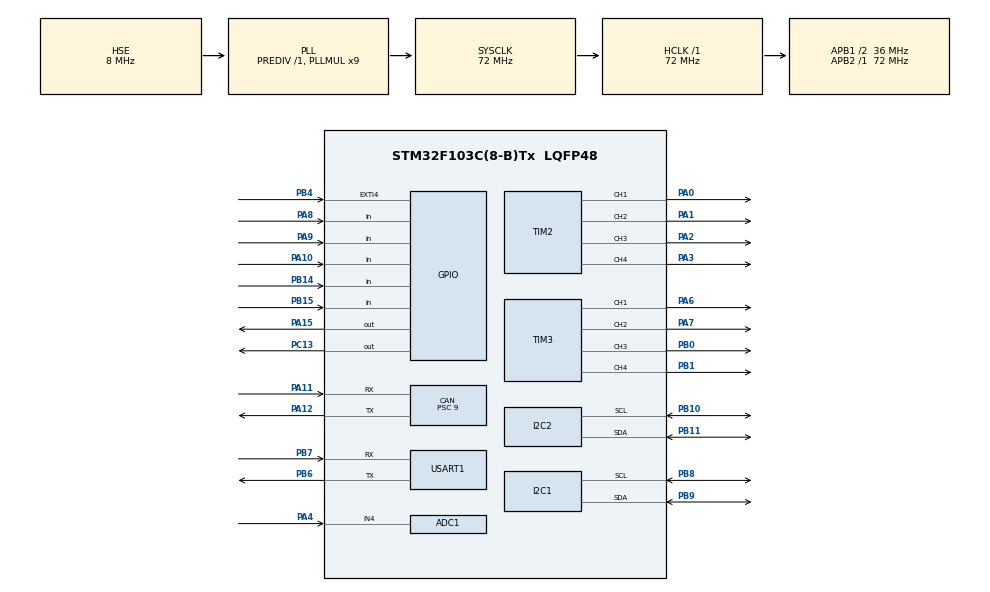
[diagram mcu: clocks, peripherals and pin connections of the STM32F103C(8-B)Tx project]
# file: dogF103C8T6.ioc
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ADC1.Channel-0\#ChannelRegularConversion=ADC_CHANNEL_4
ADC1.Channel-2\#ChannelRegularConversion=ADC_CHANNEL_VREFINT
ADC1.ContinuousConvMode=ENABLE
ADC1.NbrOfConversion=2
ADC1.NbrOfConversionFlag=1
ADC1.Rank-0\#ChannelRegularConversion=1
ADC1.Rank-2\#ChannelRegularConversion=2
ADC1.SamplingTime-0\#ChannelRegularConversion=ADC_SAMPLETIME_7CYCLES_5
ADC1.SamplingTime-2\#ChannelRegularConversion=ADC_SAMPLETIME_55CYCLES_5
ADC1.master=1
CAN.BS1=CAN_BS1_4TQ
CAN.BS2=CAN_BS2_3TQ
CAN.CalculateBaudRate=500000
CAN.CalculateTimeBit=2000
CAN.CalculateTimeQuantum=250.0
CAN.Mode=CAN_MODE_NORMAL
CAN.NART=ENABLE
CAN.Prescaler=9
CAN.TXFP=ENABLE
Dma.ADC1.2.Direction=DMA_PERIPH_TO_MEMORY
Dma.ADC1.2.Instance=DMA1_Channel1
Dma.ADC1.2.MemDataAlignment=DMA_MDATAALIGN_HALFWORD
Dma.ADC1.2.MemInc=DMA_MINC_ENABLE
Dma.ADC1.2.Mode=DMA_CIRCULAR
Dma.ADC1.2.PeriphDataAlignment=DMA_PDATAALIGN_HALFWORD
Dma.ADC1.2.PeriphInc=DMA_PINC_DISABLE
Dma.ADC1.2.Priority=DMA_PRIORITY_LOW
Dma.Request0=USART1_RX
Dma.Request1=USART1_TX
Dma.Request2=ADC1
Dma.USART1_RX.0.Direction=DMA_PERIPH_TO_MEMORY
Dma.USART1_RX.0.Instance=DMA1_Channel5
Dma.USART1_RX.0.MemDataAlignment=DMA_MDATAALIGN_BYTE
Dma.USART1_RX.0.MemInc=DMA_MINC_ENABLE
Dma.USART1_RX.0.Mode=DMA_NORMAL
Dma.USART1_RX.0.PeriphDataAlignment=DMA_PDATAALIGN_BYTE
Dma.USART1_RX.0.PeriphInc=DMA_PINC_DISABLE
Dma.USART1_RX.0.Priority=DMA_PRIORITY_LOW
Dma.USART1_TX.1.Direction=DMA_MEMORY_TO_PERIPH
Dma.USART1_TX.1.Instance=DMA1_Channel4
Dma.USART1_TX.1.MemDataAlignment=DMA_MDATAALIGN_BYTE
Dma.USART1_TX.1.MemInc=DMA_MINC_ENABLE
Dma.USART1_TX.1.Mode=DMA_NORMAL
Dma.USART1_TX.1.PeriphDataAlignment=DMA_PDATAALIGN_BYTE
Dma.USART1_TX.1.PeriphInc=DMA_PINC_DISABLE
Dma.USART1_TX.1.Priority=DMA_PRIORITY_LOW
FREERTOS.BinarySemaphores01=TXBinarySem,Dynamic,NULL,Available
FREERTOS.Queues01=RXQueue,16,uint8_t,0,Dynamic,NULL,NULL;KEYQueue,16,Debounce_Event_packet_t,0,Dynamic,NULL,NULL
FREERTOS.Tasks01=KEYTask,53,64,StartKEYTask,As weak,NULL,Dynamic,NULL,NULL;PARTask,46,128,StartPARTask,As weak,NULL,Dynamic,NULL,NULL;RXTask,54,182,StartRXTask,As weak,NULL,Dynamic,NULL,NULL;TXTask,39,128,StartTXTask,As weak,NULL,Dynamic,NULL,NULL;SETask,47,128,StartSETask,As weak,NULL,Dynamic,NULL,NULL;CANTask,55,64,StartCANTask,As weak,NULL,Dynamic,NULL,NULL;OLEDTask,15,128,StartOLEDTask,As weak,NULL,Dynamic,NULL,NULL
FREERTOS.configMINIMAL_STACK_SIZE=64
FREERTOS.configTOTAL_HEAP_SIZE=5000
I2C1.I2C_Mode=I2C_Fast
I2C2.I2C_Mode=I2C_Fast
Mcu.Family=STM32F1
Mcu.Name=STM32F103C(8-B)Tx
Mcu.Package=LQFP48
NVIC.CAN1_RX1_IRQn=true\:5\:0\:false\:false\:true\:true\:true\:true\:true
NVIC.DMA1_Channel1_IRQn=true\:5\:0\:false\:false\:true\:true\:false\:true\:true
NVIC.DMA1_Channel4_IRQn=true\:5\:0\:false\:false\:true\:true\:false\:true\:true
NVIC.DMA1_Channel5_IRQn=true\:5\:0\:false\:false\:true\:true\:false\:true\:true
NVIC.PriorityGroup=NVIC_PRIORITYGROUP_4
NVIC.TIM4_IRQn=true\:15\:0\:false\:false\:true\:false\:false\:true\:true
NVIC.TimeBase=TIM4_IRQn
NVIC.TimeBaseIP=TIM4
NVIC.USART1_IRQn=true\:5\:0\:false\:false\:true\:true\:true\:true\:true
NVIC.USB_LP_CAN1_RX0_IRQn=true\:5\:0\:false\:false\:true\:true\:true\:true\:true
PA0-WKUP.Signal=S_TIM2_CH1_ETR
PA1.Signal=S_TIM2_CH2
PA10.GPIO_PuPd=GPIO_PULLUP
PA10.Signal=GPIO_Input
PA11.Mode=CAN_Activate
PA11.Signal=CAN_RX
PA12.Mode=CAN_Activate
PA12.Signal=CAN_TX
PA13.Mode=Serial_Wire
PA13.Signal=SYS_JTMS-SWDIO
PA14.Mode=Serial_Wire
PA14.Signal=SYS_JTCK-SWCLK
PA15.GPIO_ModeDefaultOutputPP=GPIO_MODE_OUTPUT_PP
PA15.GPIO_PuPd=GPIO_PULLUP
PA15.PinState=GPIO_PIN_SET
PA15.Signal=GPIO_Output
PA2.Signal=S_TIM2_CH3
PA3.Signal=S_TIM2_CH4
PA4.Signal=ADCx_IN4
PA6.Signal=S_TIM3_CH1
PA7.Signal=S_TIM3_CH2
PA8.GPIO_PuPd=GPIO_PULLUP
PA8.Signal=GPIO_Input
PA9.GPIO_PuPd=GPIO_PULLUP
PA9.Signal=GPIO_Input
PB0.Signal=S_TIM3_CH3
PB1.Signal=S_TIM3_CH4
PB10.Mode=I2C
PB10.Signal=I2C2_SCL
PB11.Mode=I2C
PB11.Signal=I2C2_SDA
PB14.GPIO_PuPd=GPIO_PULLUP
PB14.Signal=GPIO_Input
PB15.GPIO_PuPd=GPIO_PULLUP
PB15.Signal=GPIO_Input
PB4.Signal=GPXTI4
PB6.Mode=Asynchronous
PB6.Signal=USART1_TX
PB7.Mode=Asynchronous
PB7.Signal=USART1_RX
PB8.Mode=I2C
PB8.Signal=I2C1_SCL
PB9.Mode=I2C
PB9.Signal=I2C1_SDA
PC13-TAMPER-RTC.GPIO_ModeDefaultOutputPP=GPIO_MODE_OUTPUT_OD
PC13-TAMPER-RTC.GPIO_PuPd=GPIO_NOPULL
PC13-TAMPER-RTC.PinState=GPIO_PIN_SET
PC13-TAMPER-RTC.Signal=GPIO_Output
PD0-OSC_IN.Mode=HSE-External-Oscillator
PD0-OSC_IN.Signal=RCC_OSC_IN
PD1-OSC_OUT.Mode=HSE-External-Oscillator
PD1-OSC_OUT.Signal=RCC_OSC_OUT
ProjectManager.HeapSize=0x200
ProjectManager.StackSize=0x400
ProjectManager.TargetToolchain=CMake
RCC.ADCPresc=RCC_ADCPCLK2_DIV6
RCC.AHBFreq_Value=72000000
RCC.APB1CLKDivider=RCC_HCLK_DIV2
RCC.APB1Freq_Value=36000000
RCC.APB1TimFreq_Value=72000000
RCC.APB2Freq_Value=72000000
RCC.APB2TimFreq_Value=72000000
RCC.HCLKFreq_Value=72000000
RCC.PLLMUL=RCC_PLL_MUL9
RCC.PLLSourceVirtual=RCC_PLLSOURCE_HSE
RCC.SYSCLKFreq_VALUE=72000000
RCC.SYSCLKSource=RCC_SYSCLKSOURCE_PLLCLK
RCC.USBFreq_Value=72000000
SH.ADCx_IN4.0=ADC1_IN4,IN4
SH.S_TIM2_CH1_ETR.0=TIM2_CH1,PWM Generation1 CH1
SH.S_TIM2_CH2.0=TIM2_CH2,PWM Generation2 CH2
SH.S_TIM2_CH3.0=TIM2_CH3,PWM Generation3 CH3
SH.S_TIM2_CH4.0=TIM2_CH4,PWM Generation4 CH4
SH.S_TIM3_CH1.0=TIM3_CH1,PWM Generation1 CH1
SH.S_TIM3_CH2.0=TIM3_CH2,PWM Generation2 CH2
SH.S_TIM3_CH3.0=TIM3_CH3,PWM Generation3 CH3
SH.S_TIM3_CH4.0=TIM3_CH4,PWM Generation4 CH4
TIM2.Channel-PWM\ Generation1\ CH1=TIM_CHANNEL_1
TIM2.Channel-PWM\ Generation2\ CH2=TIM_CHANNEL_2
TIM2.Channel-PWM\ Generation3\ CH3=TIM_CHANNEL_3
TIM2.Channel-PWM\ Generation4\ CH4=TIM_CHANNEL_4
TIM3.Channel-PWM\ Generation1\ CH1=TIM_CHANNEL_1
TIM3.Channel-PWM\ Generation2\ CH2=TIM_CHANNEL_2
TIM3.Channel-PWM\ Generation3\ CH3=TIM_CHANNEL_3
TIM3.Channel-PWM\ Generation4\ CH4=TIM_CHANNEL_4
USART1.VirtualMode=VM_ASYNC
VP_ADC1_Vref_Input.Mode=IN-Vrefint
VP_FREERTOS_VS_CMSIS_V2.Mode=CMSIS_V2
VP_SYS_VS_tim4.Mode=TIM4
VP_TIM2_VS_ClockSourceINT.Mode=Internal
VP_TIM3_VS_ClockSourceINT.Mode=Internal
board=custom

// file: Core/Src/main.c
/* USER CODE BEGIN Header */
/**
  ******************************************************************************
  * @file           : main.c
  * @brief          : Main program body
  ******************************************************************************
  * @attention
  *
  * Copyright (c) 2026 STMicroelectronics.
  * All rights reserved.
  *
  * This software is licensed under terms that can be found in the LICENSE file
  * in the root directory of this software component.
  * If no LICENSE file comes with this software, it is provided AS-IS.
  *
  ******************************************************************************
  */
/* USER CODE END Header */
#include "main.h"
#include "cmsis_os.h"
#include "adc.h"
#include "can.h"
#include "dma.h"
#include "i2c.h"
#include "tim.h"
#include "usart.h"
#include "gpio.h"

void SystemClock_Config(void);
void MX_FREERTOS_Init(void);

int main(void)
{

  /* MCU Configuration--------------------------------------------------------*/

  /* Reset of all peripherals, Initializes the Flash interface and the Systick. */
  HAL_Init();

  /* Configure the system clock */
  SystemClock_Config();

  /* Initialize all configured peripherals */
  MX_GPIO_Init();
  MX_DMA_Init();
  MX_USART1_UART_Init();
  MX_TIM3_Init();
  MX_CAN_Init();
  MX_TIM2_Init();
  MX_ADC1_Init();
  MX_I2C1_Init();
  MX_I2C2_Init();

  /* Init scheduler */
  osKernelInitialize();  /* Call init function for freertos objects (in cmsis_os2.c) */
  MX_FREERTOS_Init();

  /* Start scheduler */
  osKernelStart();

  /* We should never get here as control is now taken by the scheduler */

  /* Infinite loop */
  while (1)
  {

  }
}

void SystemClock_Config(void)
{
  RCC_OscInitTypeDef RCC_OscInitStruct = {0};
  RCC_ClkInitTypeDef RCC_ClkInitStruct = {0};
  RCC_PeriphCLKInitTypeDef PeriphClkInit = {0};

  /** Initializes the RCC Oscillators according to the specified parameters
  * in the RCC_OscInitTypeDef structure.
  */
  RCC_OscInitStruct.OscillatorType = RCC_OSCILLATORTYPE_HSE;
  RCC_OscInitStruct.HSEState = RCC_HSE_ON;
  RCC_OscInitStruct.HSEPredivValue = RCC_HSE_PREDIV_DIV1;
  RCC_OscInitStruct.HSIState = RCC_HSI_ON;
  RCC_OscInitStruct.PLL.PLLState = RCC_PLL_ON;
  RCC_OscInitStruct.PLL.PLLSource = RCC_PLLSOURCE_HSE;
  RCC_OscInitStruct.PLL.PLLMUL = RCC_PLL_MUL9;
  if (HAL_RCC_OscConfig(&RCC_OscInitStruct) != HAL_OK)
  {
    Error_Handler();
  }

  /** Initializes the CPU, AHB and APB buses clocks
  */
  RCC_ClkInitStruct.ClockType = RCC_CLOCKTYPE_HCLK|RCC_CLOCKTYPE_SYSCLK
                              |RCC_CLOCKTYPE_PCLK1|RCC_CLOCKTYPE_PCLK2;
  RCC_ClkInitStruct.SYSCLKSource = RCC_SYSCLKSOURCE_PLLCLK;
  RCC_ClkInitStruct.AHBCLKDivider = RCC_SYSCLK_DIV1;
  RCC_ClkInitStruct.APB1CLKDivider = RCC_HCLK_DIV2;
  RCC_ClkInitStruct.APB2CLKDivider = RCC_HCLK_DIV1;

  if (HAL_RCC_ClockConfig(&RCC_ClkInitStruct, FLASH_LATENCY_2) != HAL_OK)
  {
    Error_Handler();
  }
  PeriphClkInit.PeriphClockSelection = RCC_PERIPHCLK_ADC;
  PeriphClkInit.AdcClockSelection = RCC_ADCPCLK2_DIV6;
  if (HAL_RCCEx_PeriphCLKConfig(&PeriphClkInit) != HAL_OK)
  {
    Error_Handler();
  }
}

void HAL_TIM_PeriodElapsedCallback(TIM_HandleTypeDef *htim)
{
  if (htim->Instance == TIM4)
  {
    HAL_IncTick();
  }
}

void Error_Handler(void)
{
  __disable_irq();
  while (1)
  {
  }
}

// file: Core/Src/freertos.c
/* USER CODE BEGIN Header */
/**
  ******************************************************************************
  * File Name          : freertos.c
  * Description        : Code for freertos applications
  ******************************************************************************
  * @attention
  *
  * Copyright (c) 2026 STMicroelectronics.
  * All rights reserved.
  *
  * This software is licensed under terms that can be found in the LICENSE file
  * in the root directory of this software component.
  * If no LICENSE file comes with this software, it is provided AS-IS.
  *
  ******************************************************************************
  */
/* USER CODE END Header */

#include "FreeRTOS.h"
#include "task.h"
#include "main.h"
#include "cmsis_os.h"

/* USER CODE BEGIN Includes */
#include "debounce.h"
/* USER CODE END Includes */

/* Definitions for KEYTask */
osThreadId_t KEYTaskHandle;
const osThreadAttr_t KEYTask_attributes = {
  .name = "KEYTask",
  .stack_size = 64 * 4,
  .priority = (osPriority_t) osPriorityRealtime5,
};
/* Definitions for PARTask */
osThreadId_t PARTaskHandle;
const osThreadAttr_t PARTask_attributes = {
  .name = "PARTask",
  .stack_size = 128 * 4,
  .priority = (osPriority_t) osPriorityHigh6,
};
/* Definitions for RXTask */
osThreadId_t RXTaskHandle;
const osThreadAttr_t RXTask_attributes = {
  .name = "RXTask",
  .stack_size = 182 * 4,
  .priority = (osPriority_t) osPriorityRealtime6,
};
/* Definitions for TXTask */
osThreadId_t TXTaskHandle;
const osThreadAttr_t TXTask_attributes = {
  .name = "TXTask",
  .stack_size = 128 * 4,
  .priority = (osPriority_t) osPriorityAboveNormal7,
};
/* Definitions for SETask */
osThreadId_t SETaskHandle;
const osThreadAttr_t SETask_attributes = {
  .name = "SETask",
  .stack_size = 128 * 4,
  .priority = (osPriority_t) osPriorityHigh7,
};
/* Definitions for CANTask */
osThreadId_t CANTaskHandle;
const osThreadAttr_t CANTask_attributes = {
  .name = "CANTask",
  .stack_size = 64 * 4,
  .priority = (osPriority_t) osPriorityRealtime7,
};
/* Definitions for OLEDTask */
osThreadId_t OLEDTaskHandle;
const osThreadAttr_t OLEDTask_attributes = {
  .name = "OLEDTask",
  .stack_size = 128 * 4,
  .priority = (osPriority_t) osPriorityLow7,
};
/* Definitions for RXQueue */
osMessageQueueId_t RXQueueHandle;
const osMessageQueueAttr_t RXQueue_attributes = {
  .name = "RXQueue"
};
/* Definitions for KEYQueue */
osMessageQueueId_t KEYQueueHandle;
const osMessageQueueAttr_t KEYQueue_attributes = {
  .name = "KEYQueue"
};
/* Definitions for TXBinarySem */
osSemaphoreId_t TXBinarySemHandle;
const osSemaphoreAttr_t TXBinarySem_attributes = {
  .name = "TXBinarySem"
};

void StartKEYTask(void *argument);
void StartPARTask(void *argument);
void StartRXTask(void *argument);
void StartTXTask(void *argument);
void StartSETask(void *argument);
void StartCANTask(void *argument);
void StartOLEDTask(void *argument);

void MX_FREERTOS_Init(void); /* (MISRA C 2004 rule 8.1) */

void MX_FREERTOS_Init(void) {

  /* Create the semaphores(s) */
  /* creation of TXBinarySem */
  TXBinarySemHandle = osSemaphoreNew(1, 1, &TXBinarySem_attributes);

  /* Create the queue(s) */
  /* creation of RXQueue */
  RXQueueHandle = osMessageQueueNew (16, sizeof(uint8_t), &RXQueue_attributes);

  /* creation of KEYQueue */
  KEYQueueHandle = osMessageQueueNew (16, sizeof(Debounce_Event_packet_t), &KEYQueue_attributes);

  /* Create the thread(s) */
  /* creation of KEYTask */
  KEYTaskHandle = osThreadNew(StartKEYTask, NULL, &KEYTask_attributes);

  /* creation of PARTask */
  PARTaskHandle = osThreadNew(StartPARTask, NULL, &PARTask_attributes);

  /* creation of RXTask */
  RXTaskHandle = osThreadNew(StartRXTask, NULL, &RXTask_attributes);

  /* creation of TXTask */
  TXTaskHandle = osThreadNew(StartTXTask, NULL, &TXTask_attributes);

  /* creation of SETask */
  SETaskHandle = osThreadNew(StartSETask, NULL, &SETask_attributes);

  /* creation of CANTask */
  CANTaskHandle = osThreadNew(StartCANTask, NULL, &CANTask_attributes);

  /* creation of OLEDTask */
  OLEDTaskHandle = osThreadNew(StartOLEDTask, NULL, &OLEDTask_attributes);

}

__weak void StartKEYTask(void *argument)
{
  for(;;)
  {
    osDelay(1);
  }
}

__weak void StartPARTask(void *argument)
{
  for(;;)
  {
    osDelay(1);
  }
}

__weak void StartRXTask(void *argument)
{
  for(;;)
  {
    osDelay(1);
  }
}

__weak void StartTXTask(void *argument)
{
  for(;;)
  {
    osDelay(1);
  }
}

__weak void StartSETask(void *argument)
{
  for(;;)
  {
    osDelay(1);
  }
}

__weak void StartCANTask(void *argument)
{
  for(;;)
  {
    osDelay(1);
  }
}

__weak void StartOLEDTask(void *argument)
{
  for(;;)
  {
    osDelay(1);
  }
}
